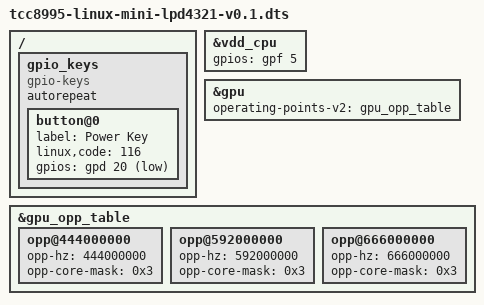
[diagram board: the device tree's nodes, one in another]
// SPDX-License-Identifier: (GPL-2.0-or-later OR MIT)
/*
 * Copyright (C) Telechips Inc.
 */

/dts-v1/;

#include "tcc8995-linux-mini.dtsi"

/ {
	/* Describe here after remove this statement if you have something to be override. */
	gpio_keys {
		compatible = "gpio-keys";
		#address-cells = <1>;
		#size-cells = <0>;
		autorepeat;
		button@0 {
			label = "Power Key";
			linux,code = <116>;
			gpios = <&gpd 20 1>;
		};
	};
};

/* CPU Power Control */
&vdd_cpu {
        gpios = <&gpf 5 0x4>;
};

&gpu {
        operating-points-v2 = <&gpu_opp_table>;
};

&gpu_opp_table {
    opp@444000000 {
	opp-hz = /bits/ 64 <444000000>;
	opp-core-mask = /bits/ 64 <0x3>;
    };
    opp@592000000 {
        opp-hz = /bits/ 64 <592000000>;
        opp-core-mask = /bits/ 64 <0x3>;
    };
    opp@666000000 {
        opp-hz = /bits/ 64 <666000000>;
        opp-core-mask = /bits/ 64 <0x3>;
    };
};
